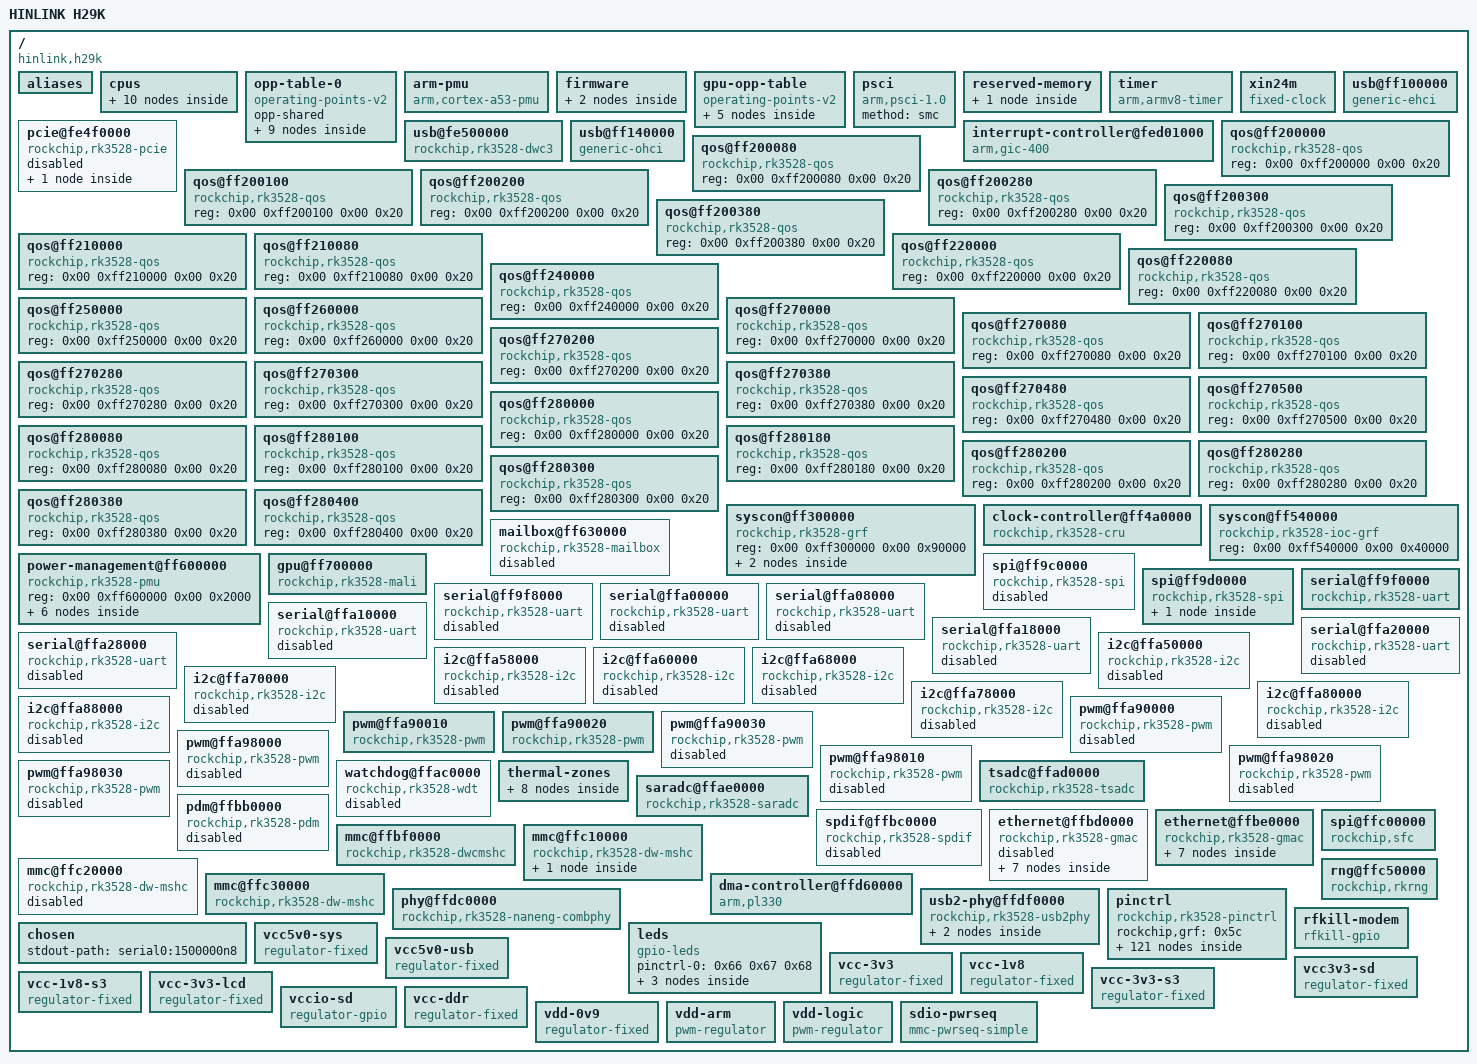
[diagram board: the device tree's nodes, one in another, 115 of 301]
/dts-v1/;

/ {
	interrupt-parent = <0x01>;
	#address-cells = <0x02>;
	#size-cells = <0x02>;
	model = "HINLINK H29K";
	compatible = "hinlink,h29k\0rockchip,rk3528";

	aliases {
		gpio0 = "/pinctrl/gpio@ff610000";
		gpio1 = "/pinctrl/gpio@ffaf0000";
		gpio2 = "/pinctrl/gpio@ffb00000";
		gpio3 = "/pinctrl/gpio@ffb10000";
		gpio4 = "/pinctrl/gpio@ffb20000";
		i2c0 = "/i2c@ffa50000";
		i2c1 = "/i2c@ffa58000";
		i2c2 = "/i2c@ffa60000";
		i2c3 = "/i2c@ffa68000";
		i2c4 = "/i2c@ffa70000";
		i2c5 = "/i2c@ffa78000";
		i2c6 = "/i2c@ffa80000";
		i2c7 = "/i2c@ffa88000";
		serial0 = "/serial@ff9f0000";
		serial1 = "/serial@ff9f8000";
		serial2 = "/serial@ffa00000";
		serial3 = "/serial@ffa08000";
		serial4 = "/serial@ffa10000";
		serial5 = "/serial@ffa18000";
		serial6 = "/serial@ffa20000";
		serial7 = "/serial@ffa28000";
		spi0 = "/spi@ff9c0000";
		spi1 = "/spi@ff9d0000";
		spi2 = "/spi@ffc00000";
		mmc0 = "/mmc@ffbf0000";
		mmc1 = "/mmc@ffc30000";
		mmc2 = "/mmc@ffc10000";
		ethernet0 = "/ethernet@ffbe0000";
		led-boot = "/leds/work";
		led-failsafe = "/leds/work";
		led-running = "/leds/work";
		led-upgrade = "/leds/work";
	};

	cpus {
		#address-cells = <0x02>;
		#size-cells = <0x00>;

		cpu-map {

			cluster0 {

				core0 {
					cpu = <0x02>;
				};

				core1 {
					cpu = <0x03>;
				};

				core2 {
					cpu = <0x04>;
				};

				core3 {
					cpu = <0x05>;
				};
			};
		};

		cpu@0 {
			device_type = "cpu";
			compatible = "arm,cortex-a53";
			reg = <0x00 0x00>;
			clocks = <0x06 0x15>;
			assigned-clocks = <0x06 0x15>;
			assigned-clock-rates = <0x47868c00>;
			dynamic-power-coefficient = <0x93>;
			#cooling-cells = <0x02>;
			enable-method = "psci";
			operating-points-v2 = <0x07>;
			cpu-supply = <0x08>;
			phandle = <0x02>;
		};

		cpu@1 {
			device_type = "cpu";
			compatible = "arm,cortex-a53";
			reg = <0x00 0x01>;
			clocks = <0x06 0x15>;
			dynamic-power-coefficient = <0x93>;
			#cooling-cells = <0x02>;
			enable-method = "psci";
			operating-points-v2 = <0x07>;
			cpu-supply = <0x08>;
			phandle = <0x03>;
		};

		cpu@2 {
			device_type = "cpu";
			compatible = "arm,cortex-a53";
			reg = <0x00 0x02>;
			clocks = <0x06 0x15>;
			dynamic-power-coefficient = <0x93>;
			#cooling-cells = <0x02>;
			enable-method = "psci";
			operating-points-v2 = <0x07>;
			cpu-supply = <0x08>;
			phandle = <0x04>;
		};

		cpu@3 {
			device_type = "cpu";
			compatible = "arm,cortex-a53";
			reg = <0x00 0x03>;
			clocks = <0x06 0x15>;
			dynamic-power-coefficient = <0x93>;
			#cooling-cells = <0x02>;
			enable-method = "psci";
			operating-points-v2 = <0x07>;
			cpu-supply = <0x08>;
			phandle = <0x05>;
		};
	};

	opp-table-0 {
		compatible = "operating-points-v2";
		opp-shared;
		phandle = <0x07>;

		opp-408000000 {
			opp-hz = <0x00 0x18519600>;
			opp-microvolt = <0xc96a8 0xc96a8 0x10c8e0>;
			clock-latency-ns = <0x9c40>;
			opp-suspend;
		};

		opp-600000000 {
			opp-hz = <0x00 0x23c34600>;
			opp-microvolt = <0xc96a8 0xc96a8 0x10c8e0>;
			clock-latency-ns = <0x9c40>;
		};

		opp-816000000 {
			opp-hz = <0x00 0x30a32c00>;
			opp-microvolt = <0xc96a8 0xc96a8 0x10c8e0>;
			clock-latency-ns = <0x9c40>;
		};

		opp-1008000000 {
			opp-hz = <0x00 0x3c14dc00>;
			opp-microvolt = <0xc96a8 0xc96a8 0x10c8e0>;
			clock-latency-ns = <0x9c40>;
		};

		opp-1200000000 {
			opp-hz = <0x00 0x47868c00>;
			opp-microvolt = <0xc96a8 0xc96a8 0x10c8e0>;
			clock-latency-ns = <0x9c40>;
		};

		opp-1416000000 {
			opp-hz = <0x00 0x54667200>;
			opp-microvolt = <0xeafc4 0xeafc4 0x10c8e0>;
			clock-latency-ns = <0x9c40>;
		};

		opp-1608000000 {
			opp-hz = <0x00 0x5fd82200>;
			opp-microvolt = <0xf7314 0xf7314 0x10c8e0>;
			clock-latency-ns = <0x9c40>;
		};

		opp-1800000000 {
			opp-hz = <0x00 0x6b49d200>;
			opp-microvolt = <0x103664 0x103664 0x10c8e0>;
			clock-latency-ns = <0x9c40>;
		};

		opp-2016000000 {
			opp-hz = <0x00 0x7829b800>;
			opp-microvolt = <0x10c8e0 0x10c8e0 0x10c8e0>;
			clock-latency-ns = <0x9c40>;
		};
	};

	arm-pmu {
		compatible = "arm,cortex-a53-pmu";
		interrupts = <0x00 0xab 0x04 0x00 0xac 0x04 0x00 0xad 0x04 0x00 0xae 0x04>;
		interrupt-affinity = <0x02 0x03 0x04 0x05>;
	};

	firmware {

		scmi {
			compatible = "arm,scmi-smc";
			arm,smc-id = <0x82000010>;
			shmem = <0x09>;
			#address-cells = <0x01>;
			#size-cells = <0x00>;

			protocol@14 {
				reg = <0x14>;
				#clock-cells = <0x01>;
				phandle = <0x06>;
			};
		};
	};

	gpu-opp-table {
		compatible = "operating-points-v2";
		phandle = <0x14>;

		opp-300000000 {
			opp-hz = <0x00 0x11e1a300>;
			opp-microvolt = <0xd59f8 0xd59f8 0xf4240>;
		};

		opp-500000000 {
			opp-hz = <0x00 0x1dcd6500>;
			opp-microvolt = <0xd59f8 0xd59f8 0xf4240>;
		};

		opp-600000000 {
			opp-hz = <0x00 0x23c34600>;
			opp-microvolt = <0xd59f8 0xd59f8 0xf4240>;
		};

		opp-700000000 {
			opp-hz = <0x00 0x29b92700>;
			opp-microvolt = <0xdbba0 0xdbba0 0xf4240>;
		};

		opp-800000000 {
			opp-hz = <0x00 0x2faf0800>;
			opp-microvolt = <0xe7ef0 0xe7ef0 0xf4240>;
		};
	};

	psci {
		compatible = "arm,psci-1.0";
		method = "smc";
	};

	reserved-memory {
		#address-cells = <0x02>;
		#size-cells = <0x02>;
		ranges;

		shmem@10f000 {
			compatible = "arm,scmi-shmem";
			reg = <0x00 0x10f000 0x00 0x100>;
			no-map;
			phandle = <0x09>;
		};
	};

	timer {
		compatible = "arm,armv8-timer";
		interrupts = <0x01 0x0d 0xf08 0x01 0x0e 0xf08 0x01 0x0b 0xf08 0x01 0x0a 0xf08>;
	};

	xin24m {
		compatible = "fixed-clock";
		#clock-cells = <0x00>;
		clock-frequency = <0x16e3600>;
		clock-output-names = "xin24m";
	};

	pcie@fe4f0000 {
		compatible = "rockchip,rk3528-pcie\0rockchip,rk3568-pcie";
		reg = <0x00 0xfe000000 0x00 0x400000 0x00 0xfe4f0000 0x00 0x10000 0x00 0xfc000000 0x00 0x100000>;
		reg-names = "dbi\0apb\0config";
		interrupts = <0x00 0x9e 0x04 0x00 0x9d 0x04 0x00 0x9c 0x04 0x00 0x9b 0x04 0x00 0x9a 0x04 0x00 0x99 0x04>;
		interrupt-names = "msi\0pmc\0sys\0legacy\0msg\0err";
		bus-range = <0x00 0xff>;
		clocks = <0x0a 0xd9 0x0a 0xda 0x0a 0xdb 0x0a 0x9e 0x0a 0xd8 0x0a 0xd7 0x0a 0xdc>;
		clock-names = "aclk\0hclk_slv\0hclk_dbi\0pclk_cru\0aux\0pclk\0pipe";
		device_type = "pci";
		#interrupt-cells = <0x01>;
		interrupt-map-mask = <0x00 0x00 0x00 0x07>;
		interrupt-map = <0x00 0x00 0x00 0x01 0x0b 0x00 0x00 0x00 0x00 0x02 0x0b 0x01 0x00 0x00 0x00 0x03 0x0b 0x02 0x00 0x00 0x00 0x04 0x0b 0x03>;
		linux,pci-domain = <0x00>;
		max-link-speed = <0x02>;
		num-ib-windows = <0x08>;
		num-ob-windows = <0x08>;
		num-viewport = <0x04>;
		num-lanes = <0x01>;
		phys = <0x0c 0x02>;
		phy-names = "pcie-phy";
		ranges = <0x1000000 0x00 0xfc100000 0x00 0xfc100000 0x00 0x100000 0x2000000 0x00 0xfc200000 0x00 0xfc200000 0x00 0x1e00000 0x3000000 0x01 0x00 0x01 0x00 0x00 0x40000000>;
		resets = <0x0a 0x1e3 0x0a 0x1e1 0x0a 0x19b>;
		reset-names = "pwr\0periph\0preset_cru";
		#address-cells = <0x03>;
		#size-cells = <0x02>;
		status = "disabled";

		legacy-interrupt-controller {
			#address-cells = <0x00>;
			#interrupt-cells = <0x01>;
			interrupt-controller;
			interrupt-parent = <0x01>;
			interrupts = <0x00 0x9b 0x01>;
			phandle = <0x0b>;
		};
	};

	usb@fe500000 {
		compatible = "rockchip,rk3528-dwc3\0snps,dwc3";
		reg = <0x00 0xfe500000 0x00 0x400000>;
		interrupts = <0x00 0x98 0x04>;
		clocks = <0x0a 0x106 0x0a 0x107 0x0a 0x105>;
		clock-names = "ref_clk\0suspend_clk\0bus_clk";
		dr_mode = "host";
		phys = <0x0d 0x0c 0x04>;
		phy-names = "usb2-phy\0usb3-phy";
		phy_type = "utmi_wide";
		snps,dis-del-phy-power-chg-quirk;
		snps,dis-tx-ipgap-linecheck-quirk;
		snps,dis-u2-freeclk-exists-quirk;
		snps,dis_enblslpm_quirk;
		snps,dis_u2_susphy_quirk;
		resets = <0x0a 0x211>;
		reset-names = "usb3-otg";
		status = "okay";
	};

	interrupt-controller@fed01000 {
		compatible = "arm,gic-400";
		#interrupt-cells = <0x03>;
		#address-cells = <0x00>;
		interrupt-controller;
		reg = <0x00 0xfed01000 0x00 0x1000 0x00 0xfed02000 0x00 0x2000 0x00 0xfed04000 0x00 0x2000 0x00 0xfed06000 0x00 0x2000>;
		interrupts = <0x01 0x09 0xf08>;
		phandle = <0x01>;
	};

	usb@ff100000 {
		compatible = "generic-ehci";
		reg = <0x00 0xff100000 0x00 0x40000>;
		interrupts = <0x00 0x8f 0x04>;
		clocks = <0x0a 0x1a0 0x0a 0x1a1 0x0e>;
		clock-names = "usbhost\0arbiter\0utmi";
		phys = <0x0f>;
		phy-names = "usb2-phy";
		status = "okay";
	};

	usb@ff140000 {
		compatible = "generic-ohci";
		reg = <0x00 0xff140000 0x00 0x40000>;
		interrupts = <0x00 0x90 0x04>;
		clocks = <0x0a 0x1a0 0x0a 0x1a1 0x0e>;
		clock-names = "usbhost\0arbiter\0utmi";
		phys = <0x0f>;
		phy-names = "usb2-phy";
		status = "okay";
	};

	qos@ff200000 {
		compatible = "rockchip,rk3528-qos\0syscon";
		reg = <0x00 0xff200000 0x00 0x20>;
	};

	qos@ff200080 {
		compatible = "rockchip,rk3528-qos\0syscon";
		reg = <0x00 0xff200080 0x00 0x20>;
	};

	qos@ff200100 {
		compatible = "rockchip,rk3528-qos\0syscon";
		reg = <0x00 0xff200100 0x00 0x20>;
	};

	qos@ff200200 {
		compatible = "rockchip,rk3528-qos\0syscon";
		reg = <0x00 0xff200200 0x00 0x20>;
	};

	qos@ff200280 {
		compatible = "rockchip,rk3528-qos\0syscon";
		reg = <0x00 0xff200280 0x00 0x20>;
	};

	qos@ff200300 {
		compatible = "rockchip,rk3528-qos\0syscon";
		reg = <0x00 0xff200300 0x00 0x20>;
	};

	qos@ff200380 {
		compatible = "rockchip,rk3528-qos\0syscon";
		reg = <0x00 0xff200380 0x00 0x20>;
	};

	qos@ff210000 {
		compatible = "rockchip,rk3528-qos\0syscon";
		reg = <0x00 0xff210000 0x00 0x20>;
	};

	qos@ff210080 {
		compatible = "rockchip,rk3528-qos\0syscon";
		reg = <0x00 0xff210080 0x00 0x20>;
	};

	qos@ff220000 {
		compatible = "rockchip,rk3528-qos\0syscon";
		reg = <0x00 0xff220000 0x00 0x20>;
		phandle = <0x11>;
	};

	qos@ff220080 {
		compatible = "rockchip,rk3528-qos\0syscon";
		reg = <0x00 0xff220080 0x00 0x20>;
		phandle = <0x12>;
	};

	qos@ff240000 {
		compatible = "rockchip,rk3528-qos\0syscon";
		reg = <0x00 0xff240000 0x00 0x20>;
	};

	qos@ff250000 {
		compatible = "rockchip,rk3528-qos\0syscon";
		reg = <0x00 0xff250000 0x00 0x20>;
	};

	qos@ff260000 {
		compatible = "rockchip,rk3528-qos\0syscon";
		reg = <0x00 0xff260000 0x00 0x20>;
	};

	qos@ff270000 {
		compatible = "rockchip,rk3528-qos\0syscon";
		reg = <0x00 0xff270000 0x00 0x20>;
	};

	qos@ff270080 {
		compatible = "rockchip,rk3528-qos\0syscon";
		reg = <0x00 0xff270080 0x00 0x20>;
	};

	qos@ff270100 {
		compatible = "rockchip,rk3528-qos\0syscon";
		reg = <0x00 0xff270100 0x00 0x20>;
	};

	qos@ff270200 {
		compatible = "rockchip,rk3528-qos\0syscon";
		reg = <0x00 0xff270200 0x00 0x20>;
	};

	qos@ff270280 {
		compatible = "rockchip,rk3528-qos\0syscon";
		reg = <0x00 0xff270280 0x00 0x20>;
	};

	qos@ff270300 {
		compatible = "rockchip,rk3528-qos\0syscon";
		reg = <0x00 0xff270300 0x00 0x20>;
	};

	qos@ff270380 {
		compatible = "rockchip,rk3528-qos\0syscon";
		reg = <0x00 0xff270380 0x00 0x20>;
	};

	qos@ff270480 {
		compatible = "rockchip,rk3528-qos\0syscon";
		reg = <0x00 0xff270480 0x00 0x20>;
	};

	qos@ff270500 {
		compatible = "rockchip,rk3528-qos\0syscon";
		reg = <0x00 0xff270500 0x00 0x20>;
	};

	qos@ff280000 {
		compatible = "rockchip,rk3528-qos\0syscon";
		reg = <0x00 0xff280000 0x00 0x20>;
	};

	qos@ff280080 {
		compatible = "rockchip,rk3528-qos\0syscon";
		reg = <0x00 0xff280080 0x00 0x20>;
	};

	qos@ff280100 {
		compatible = "rockchip,rk3528-qos\0syscon";
		reg = <0x00 0xff280100 0x00 0x20>;
	};

	qos@ff280180 {
		compatible = "rockchip,rk3528-qos\0syscon";
		reg = <0x00 0xff280180 0x00 0x20>;
	};

	qos@ff280200 {
		compatible = "rockchip,rk3528-qos\0syscon";
		reg = <0x00 0xff280200 0x00 0x20>;
	};

	qos@ff280280 {
		compatible = "rockchip,rk3528-qos\0syscon";
		reg = <0x00 0xff280280 0x00 0x20>;
	};

	qos@ff280300 {
		compatible = "rockchip,rk3528-qos\0syscon";
		reg = <0x00 0xff280300 0x00 0x20>;
	};

	qos@ff280380 {
		compatible = "rockchip,rk3528-qos\0syscon";
		reg = <0x00 0xff280380 0x00 0x20>;
	};

	qos@ff280400 {
		compatible = "rockchip,rk3528-qos\0syscon";
		reg = <0x00 0xff280400 0x00 0x20>;
	};

	syscon@ff300000 {
		compatible = "rockchip,rk3528-grf\0syscon\0simple-mfd";
		reg = <0x00 0xff300000 0x00 0x90000>;
		phandle = <0x10>;

		grf-clock-controller {
			compatible = "rockchip,rk3528-grf-cru";
			#clock-cells = <0x01>;
			phandle = <0x4f>;
		};

		reboot-mode {
			compatible = "syscon-reboot-mode";
			offset = <0x70200>;
			mode-bootloader = <0x5242c301>;
			mode-fastboot = <0x5242c309>;
			mode-loader = <0x5242c301>;
			mode-normal = <0x5242c300>;
			mode-recovery = <0x5242c303>;
		};
	};

	clock-controller@ff4a0000 {
		compatible = "rockchip,rk3528-cru";
		reg = <0x00 0xff4a0000 0x00 0x30000>;
		rockchip,grf = <0x10>;
		#clock-cells = <0x01>;
		#reset-cells = <0x01>;
		assigned-clocks = <0x0a 0x1ff 0x0a 0x03 0x0a 0x04 0x0a 0x02 0x0a 0x0d 0x0a 0x11 0x0a 0x09 0x0a 0x0a 0x0a 0x0b 0x0a 0x0c 0x0a 0x0e 0x0a 0x0f 0x0a 0x10 0x0a 0x12 0x0a 0x90 0x0a 0x8f 0x0a 0x95 0x0a 0x55 0x0a 0x144 0x0a 0x96 0x0a 0x93>;
		assigned-clock-rates = <0x8000 0x46cf7100 0x3b9aca00 0x3b5dc100 0xee6b280 0x1dcd6500 0x2faf080 0x5f5e100 0x8f0d180 0xbebc200 0x11e1a300 0x1443fd00 0x17d78400 0x23c34600 0x2faf080 0x5f5e100 0x7735940 0x1dcd6500 0x1443fd00 0x11e1a300 0xbebc200>;
		phandle = <0x0a>;
	};

	syscon@ff540000 {
		compatible = "rockchip,rk3528-ioc-grf\0syscon";
		reg = <0x00 0xff540000 0x00 0x40000>;
		phandle = <0x5c>;
	};

	power-management@ff600000 {
		compatible = "rockchip,rk3528-pmu\0syscon\0simple-mfd";
		reg = <0x00 0xff600000 0x00 0x2000>;

		power-controller {
			compatible = "rockchip,rk3528-power-controller";
			#power-domain-cells = <0x01>;
			#address-cells = <0x01>;
			#size-cells = <0x00>;
			phandle = <0x13>;

			pd_gpu@4 {
				reg = <0x04>;
				clocks = <0x0a 0x113 0x0a 0x10e>;
				pm_qos = <0x11 0x12>;
			};

			pd_rkvdec@5 {
				reg = <0x05>;
			};

			pd_rkvenc@6 {
				reg = <0x06>;
			};

			pd_vo@7 {
				reg = <0x07>;
			};

			pd_vpu@8 {
				reg = <0x08>;
			};
		};
	};

	mailbox@ff630000 {
		compatible = "rockchip,rk3528-mailbox\0rockchip,rk3368-mailbox";
		reg = <0x00 0xff630000 0x00 0x200>;
		interrupts = <0x00 0x3c 0x04>;
		clocks = <0x0a 0x20a>;
		clock-names = "pclk_mailbox";
		#mbox-cells = <0x01>;
		status = "disabled";
	};

	gpu@ff700000 {
		compatible = "rockchip,rk3528-mali\0arm,mali-450";
		reg = <0x00 0xff700000 0x00 0x40000>;
		interrupts = <0x00 0x58 0x04 0x00 0x59 0x04 0x00 0x56 0x04 0x00 0x5c 0x04 0x00 0x5d 0x04 0x00 0x5a 0x04 0x00 0x5b 0x04>;
		interrupt-names = "gp\0gpmmu\0pp\0pp0\0ppmmu0\0pp1\0ppmmu1";
		clocks = <0x0a 0x113 0x0a 0x10e>;
		clock-names = "bus\0core";
		assigned-clocks = <0x06 0x16>;
		assigned-clock-rates = <0x11e1a300>;
		power-domains = <0x13 0x04>;
		operating-points-v2 = <0x14>;
		rockchip,grf = <0x10>;
		#cooling-cells = <0x02>;
		status = "okay";
		mali-supply = <0x15>;
		phandle = <0x33>;
	};

	spi@ff9c0000 {
		compatible = "rockchip,rk3528-spi\0rockchip,rk3066-spi";
		reg = <0x00 0xff9c0000 0x00 0x1000>;
		interrupts = <0x00 0x83 0x04>;
		#address-cells = <0x01>;
		#size-cells = <0x00>;
		clocks = <0x0a 0x12a 0x0a 0x129 0x0a 0x12b>;
		clock-names = "spiclk\0apb_pclk\0sclk_in";
		dmas = <0x16 0x19 0x16 0x18>;
		dma-names = "tx\0rx";
		pinctrl-names = "default";
		pinctrl-0 = <0x17 0x18 0x19>;
		status = "disabled";
	};

	spi@ff9d0000 {
		compatible = "rockchip,rk3528-spi\0rockchip,rk3066-spi";
		reg = <0x00 0xff9d0000 0x00 0x1000>;
		interrupts = <0x00 0x84 0x04>;
		#address-cells = <0x01>;
		#size-cells = <0x00>;
		clocks = <0x0a 0xbe 0x0a 0xbd 0x0a 0xbf>;
		clock-names = "spiclk\0apb_pclk\0sclk_in";
		dmas = <0x16 0x1f 0x16 0x1e>;
		dma-names = "tx\0rx";
		pinctrl-names = "default";
		pinctrl-0 = <0x1a 0x1b>;
		status = "okay";
		assigned-clocks = <0x0a 0xbe>;
		assigned-clock-rates = <0xbebc200>;
		num-cs = <0x01>;

		panel@0 {
			compatible = "sitronix,st7789v";
			reg = <0x00>;
			power-supply = <0x1c>;
			pinctrl-names = "default";
			pinctrl-0 = <0x1d>;
			dc-gpios = <0x1e 0x0c 0x00>;
			backlight-gpios = <0x1f 0x00 0x01>;
			spi-max-frequency = <0x5b8d80>;
			width = <0xaa>;
			height = <0x140>;
			buswidth = <0x08>;
			rotate = <0x10e>;
			debug = <0x00>;
			spi-cpol;
			spi-cpha;
		};
	};

	serial@ff9f0000 {
		compatible = "rockchip,rk3528-uart\0snps,dw-apb-uart";
		reg = <0x00 0xff9f0000 0x00 0x100>;
		interrupts = <0x00 0x28 0x04>;
		clocks = <0x0a 0x15 0x0a 0x75>;
		clock-names = "baudclk\0apb_pclk";
		reg-shift = <0x02>;
		reg-io-width = <0x04>;
		dmas = <0x16 0x09 0x16 0x08>;
		status = "okay";
		pinctrl-names = "default";
		pinctrl-0 = <0x20>;
	};

	serial@ff9f8000 {
		compatible = "rockchip,rk3528-uart\0snps,dw-apb-uart";
		reg = <0x00 0xff9f8000 0x00 0x100>;
		interrupts = <0x00 0x29 0x04>;
		clocks = <0x0a 0x18 0x0a 0x13b>;
		clock-names = "baudclk\0apb_pclk";
		reg-shift = <0x02>;
		reg-io-width = <0x04>;
		dmas = <0x16 0x0b 0x16 0x0a>;
		status = "disabled";
	};

	serial@ffa00000 {
		compatible = "rockchip,rk3528-uart\0snps,dw-apb-uart";
		reg = <0x00 0xffa00000 0x00 0x100>;
		interrupts = <0x00 0x2a 0x04>;
		clocks = <0x0a 0x1b 0x0a 0xc0>;
		clock-names = "baudclk\0apb_pclk";
		reg-shift = <0x02>;
		reg-io-width = <0x04>;
		dmas = <0x16 0x0d 0x16 0x0c>;
		status = "disabled";
	};

	serial@ffa08000 {
		compatible = "rockchip,rk3528-uart\0snps,dw-apb-uart";
		reg = <0x00 0xffa08000 0x00 0x100>;
		interrupts = <0x00 0x2b 0x04>;
		clocks = <0x0a 0x1e 0x0a 0x13d>;
		clock-names = "baudclk\0apb_pclk";
		reg-shift = <0x02>;
		reg-io-width = <0x04>;
		dmas = <0x16 0x0f 0x16 0x0e>;
		status = "disabled";
	};

	serial@ffa10000 {
		compatible = "rockchip,rk3528-uart\0snps,dw-apb-uart";
		reg = <0x00 0xffa10000 0x00 0x100>;
		interrupts = <0x00 0x2c 0x04>;
		clocks = <0x0a 0x21 0x0a 0x1a4>;
		clock-names = "baudclk\0apb_pclk";
		reg-shift = <0x02>;
		reg-io-width = <0x04>;
		dmas = <0x16 0x11 0x16 0x10>;
		status = "disabled";
	};

	serial@ffa18000 {
		compatible = "rockchip,rk3528-uart\0snps,dw-apb-uart";
		reg = <0x00 0xffa18000 0x00 0x100>;
		interrupts = <0x00 0x2d 0x04>;
		clocks = <0x0a 0x24 0x0a 0xc2>;
		clock-names = "baudclk\0apb_pclk";
		reg-shift = <0x02>;
		reg-io-width = <0x04>;
		dmas = <0x16 0x13 0x16 0x12>;
		status = "disabled";
	};

	serial@ffa20000 {
		compatible = "rockchip,rk3528-uart\0snps,dw-apb-uart";
		reg = <0x00 0xffa20000 0x00 0x100>;
		interrupts = <0x00 0x2e 0x04>;
		clocks = <0x0a 0x27 0x0a 0xc4>;
		clock-names = "baudclk\0apb_pclk";
		reg-shift = <0x02>;
		reg-io-width = <0x04>;
		dmas = <0x16 0x15 0x16 0x14>;
		status = "disabled";
	};

	serial@ffa28000 {
		compatible = "rockchip,rk3528-uart\0snps,dw-apb-uart";
		reg = <0x00 0xffa28000 0x00 0x100>;
		interrupts = <0x00 0x2f 0x04>;
		clocks = <0x0a 0x2a 0x0a 0xc6>;
		clock-names = "baudclk\0apb_pclk";
		reg-shift = <0x02>;
		reg-io-width = <0x04>;
		dmas = <0x16 0x17 0x16 0x16>;
		status = "disabled";
	};

	i2c@ffa50000 {
		compatible = "rockchip,rk3528-i2c\0rockchip,rk3399-i2c";
		reg = <0x00 0xffa50000 0x00 0x1000>;
		clocks = <0x0a 0x127 0x0a 0x126>;
		clock-names = "i2c\0pclk";
		interrupts = <0x00 0x3d 0x04>;
		pinctrl-names = "default";
		pinctrl-0 = <0x21>;
		#address-cells = <0x01>;
		#size-cells = <0x00>;
		status = "disabled";
	};

	i2c@ffa58000 {
		compatible = "rockchip,rk3528-i2c\0rockchip,rk3399-i2c";
		reg = <0x00 0xffa58000 0x00 0x1000>;
		clocks = <0x0a 0x125 0x0a 0x124>;
		clock-names = "i2c\0pclk";
		interrupts = <0x00 0x3e 0x04>;
		pinctrl-names = "default";
		pinctrl-0 = <0x22>;
		#address-cells = <0x01>;
		#size-cells = <0x00>;
		status = "disabled";
	};

	i2c@ffa60000 {
		compatible = "rockchip,rk3528-i2c\0rockchip,rk3399-i2c";
		reg = <0x00 0xffa60000 0x00 0x1000>;
		clocks = <0x0a 0x1f2 0x0a 0x1f1>;
		clock-names = "i2c\0pclk";
		interrupts = <0x00 0x3f 0x04>;
		pinctrl-names = "default";
		pinctrl-0 = <0x23>;
		#address-cells = <0x01>;
		#size-cells = <0x00>;
		status = "disabled";
	};

	i2c@ffa68000 {
		compatible = "rockchip,rk3528-i2c\0rockchip,rk3399-i2c";
		reg = <0x00 0xffa68000 0x00 0x1000>;
		clocks = <0x0a 0xc9 0x0a 0xc8>;
		clock-names = "i2c\0pclk";
		interrupts = <0x00 0x40 0x04>;
		pinctrl-names = "default";
		pinctrl-0 = <0x24>;
		#address-cells = <0x01>;
		#size-cells = <0x00>;
		status = "disabled";
	};

	i2c@ffa70000 {
		compatible = "rockchip,rk3528-i2c\0rockchip,rk3399-i2c";
		reg = <0x00 0xffa70000 0x00 0x1000>;
		clocks = <0x0a 0x1a7 0x0a 0x1a6>;
		clock-names = "i2c\0pclk";
		interrupts = <0x00 0x41 0x04>;
		pinctrl-names = "default";
		pinctrl-0 = <0x25>;
		#address-cells = <0x01>;
		#size-cells = <0x00>;
		status = "disabled";
	};

	i2c@ffa78000 {
		compatible = "rockchip,rk3528-i2c\0rockchip,rk3399-i2c";
		reg = <0x00 0xffa78000 0x00 0x1000>;
		clocks = <0x0a 0xcb 0x0a 0xca>;
		clock-names = "i2c\0pclk";
		interrupts = <0x00 0x42 0x04>;
		pinctrl-names = "default";
		pinctrl-0 = <0x26>;
		#address-cells = <0x01>;
		#size-cells = <0x00>;
		status = "disabled";
	};

	i2c@ffa80000 {
		compatible = "rockchip,rk3528-i2c\0rockchip,rk3399-i2c";
		reg = <0x00 0xffa80000 0x00 0x1000>;
		clocks = <0x0a 0xcd 0x0a 0xcc>;
		clock-names = "i2c\0pclk";
		interrupts = <0x00 0x43 0x04>;
		pinctrl-names = "default";
		pinctrl-0 = <0x27>;
		#address-cells = <0x01>;
		#size-cells = <0x00>;
		status = "disabled";
	};

	i2c@ffa88000 {
		compatible = "rockchip,rk3528-i2c\0rockchip,rk3399-i2c";
		reg = <0x00 0xffa88000 0x00 0x1000>;
		clocks = <0x0a 0x1a9 0x0a 0x1a8>;
		clock-names = "i2c\0pclk";
		interrupts = <0x00 0x44 0x04>;
		pinctrl-names = "default";
		pinctrl-0 = <0x28>;
		#address-cells = <0x01>;
		#size-cells = <0x00>;
		status = "disabled";
	};

	pwm@ffa90000 {
		compatible = "rockchip,rk3528-pwm\0rockchip,rk3328-pwm";
		reg = <0x00 0xffa90000 0x00 0x10>;
		clocks = <0x0a 0x7f 0x0a 0x7e>;
		clock-names = "pwm\0pclk";
		pinctrl-0 = <0x29>;
		pinctrl-names = "active";
		#pwm-cells = <0x03>;
		status = "disabled";
	};

	pwm@ffa90010 {
		compatible = "rockchip,rk3528-pwm\0rockchip,rk3328-pwm";
		reg = <0x00 0xffa90010 0x00 0x10>;
		clocks = <0x0a 0x7f 0x0a 0x7e>;
		clock-names = "pwm\0pclk";
		pinctrl-0 = <0x2a>;
		pinctrl-names = "active";
		#pwm-cells = <0x03>;
		status = "okay";
		phandle = <0x69>;
	};

	pwm@ffa90020 {
		compatible = "rockchip,rk3528-pwm\0rockchip,rk3328-pwm";
		reg = <0x00 0xffa90020 0x00 0x10>;
		clocks = <0x0a 0x7f 0x0a 0x7e>;
		clock-names = "pwm\0pclk";
		pinctrl-0 = <0x2b>;
		pinctrl-names = "active";
		#pwm-cells = <0x03>;
		status = "okay";
		phandle = <0x6a>;
	};

	pwm@ffa90030 {
		compatible = "rockchip,rk3528-pwm\0rockchip,rk3328-pwm";
		reg = <0x00 0xffa90030 0x00 0x10>;
		clocks = <0x0a 0x7f 0x0a 0x7e>;
		clock-names = "pwm\0pclk";
		pinctrl-0 = <0x2c>;
		pinctrl-names = "active";
		#pwm-cells = <0x03>;
		status = "disabled";
	};

	pwm@ffa98000 {
		compatible = "rockchip,rk3528-pwm\0rockchip,rk3328-pwm";
		reg = <0x00 0xffa98000 0x00 0x10>;
		clocks = <0x0a 0x82 0x0a 0x81>;
		clock-names = "pwm\0pclk";
		pinctrl-0 = <0x2d>;
		pinctrl-names = "active";
		#pwm-cells = <0x03>;
		status = "disabled";
	};

	pwm@ffa98010 {
		compatible = "rockchip,rk3528-pwm\0rockchip,rk3328-pwm";
		reg = <0x00 0xffa98010 0x00 0x10>;
		clocks = <0x0a 0x82 0x0a 0x81>;
		clock-names = "pwm\0pclk";
		pinctrl-0 = <0x2e>;
		pinctrl-names = "active";
		#pwm-cells = <0x03>;
		status = "disabled";
	};

	pwm@ffa98020 {
		compatible = "rockchip,rk3528-pwm\0rockchip,rk3328-pwm";
		reg = <0x00 0xffa98020 0x00 0x10>;
		clocks = <0x0a 0x82 0x0a 0x81>;
		clock-names = "pwm\0pclk";
		pinctrl-0 = <0x2f>;
		pinctrl-names = "active";
		#pwm-cells = <0x03>;
		status = "disabled";
	};

	pwm@ffa98030 {
		compatible = "rockchip,rk3528-pwm\0rockchip,rk3328-pwm";
		reg = <0x00 0xffa98030 0x00 0x10>;
		clocks = <0x0a 0x82 0x0a 0x81>;
		clock-names = "pwm\0pclk";
		pinctrl-0 = <0x30>;
		pinctrl-names = "active";
		#pwm-cells = <0x03>;
		status = "disabled";
	};

	watchdog@ffac0000 {
		compatible = "rockchip,rk3528-wdt\0snps,dw-wdt";
		reg = <0x00 0xffac0000 0x00 0x100>;
		clocks = <0x0a 0x73 0x0a 0x72>;
		clock-names = "tclk\0pclk";
		interrupts = <0x00 0x1c 0x04>;
		status = "disabled";
	};

	thermal-zones {

		soc-thermal {
			polling-delay-passive = <0x14>;
			polling-delay = <0x3e8>;
			sustainable-power = <0x27e>;
			thermal-sensors = <0x31 0x00>;

			trips {

				trip-point-0 {
					temperature = <0x17318>;
					hysteresis = <0x7d0>;
					type = "passive";
				};

				trip-point-1 {
					temperature = <0x1adb0>;
					hysteresis = <0x7d0>;
					type = "passive";
					phandle = <0x32>;
				};

				soc-crit {
					temperature = <0x1d4c0>;
					hysteresis = <0x7d0>;
					type = "critical";
				};
			};

			cooling-maps {

				map0 {
					trip = <0x32>;
					cooling-device = <0x02 0xffffffff 0xffffffff 0x03 0xffffffff 0xffffffff 0x04 0xffffffff 0xffffffff 0x05 0xffffffff 0xffffffff>;
					contribution = <0x400>;
				};

				map1 {
					trip = <0x32>;
					cooling-device = <0x33 0xffffffff 0xffffffff>;
					contribution = <0x400>;
				};
			};
		};
	};

	tsadc@ffad0000 {
		compatible = "rockchip,rk3528-tsadc";
		reg = <0x00 0xffad0000 0x00 0x400>;
		rockchip,grf = <0x10>;
		interrupts = <0x00 0x8b 0x04>;
		clocks = <0x0a 0x103 0x0a 0x104 0x0a 0x102>;
		clock-names = "tsadc\0tsadc_tsen\0apb_pclk";
		assigned-clocks = <0x0a 0x103 0x0a 0x104>;
		assigned-clock-rates = <0x124f80 0xb71b00>;
		resets = <0x0a 0x20f 0x0a 0x20e>;
		reset-names = "tsadc\0tsadc-apb";
		rockchip,hw-tshut-temp = <0x1d4c0>;
		rockchip,hw-tshut-mode = <0x00>;
		rockchip,hw-tshut-polarity = <0x00>;
		#thermal-sensor-cells = <0x01>;
		status = "okay";
		phandle = <0x31>;
	};

	saradc@ffae0000 {
		compatible = "rockchip,rk3528-saradc";
		reg = <0x00 0xffae0000 0x00 0x10000>;
		interrupts = <0x00 0x8c 0x04>;
		clocks = <0x0a 0x101 0x0a 0x100>;
		clock-names = "saradc\0apb_pclk";
		resets = <0x0a 0x20b>;
		reset-names = "saradc-apb";
		#io-channel-cells = <0x01>;
		status = "okay";
		vref-supply = <0x34>;
	};

	pdm@ffbb0000 {
		compatible = "rockchip,rk3528-pdm\0rockchip,rk3568-pdm";
		reg = <0x00 0xffbb0000 0x00 0x1000>;
		clocks = <0x0a 0x137 0x0a 0x136>;
		clock-names = "pdm_clk\0pdm_hclk";
		dmas = <0x16 0x06>;
		dma-names = "rx";
		pinctrl-names = "default";
		pinctrl-0 = <0x35 0x36 0x37 0x38 0x39 0x3a>;
		#sound-dai-cells = <0x00>;
		status = "disabled";
	};

	spdif@ffbc0000 {
		compatible = "rockchip,rk3528-spdif\0rockchip,rk3568-spdif";
		reg = <0x00 0xffbc0000 0x00 0x1000>;
		interrupts = <0x00 0x82 0x04>;
		clock-names = "mclk\0hclk";
		clocks = <0x0a 0x135 0x0a 0x134>;
		dmas = <0x16 0x07>;
		dma-names = "tx";
		pinctrl-names = "default";
		pinctrl-0 = <0x3b>;
		#sound-dai-cells = <0x00>;
		status = "disabled";
	};

	ethernet@ffbd0000 {
		compatible = "rockchip,rk3528-gmac\0snps,dwmac-4.20a";
		reg = <0x00 0xffbd0000 0x00 0x10000>;
		interrupts = <0x00 0x71 0x04 0x00 0x74 0x04>;
		interrupt-names = "macirq\0eth_wake_irq";
		clocks = <0x0a 0x17b 0x0a 0x17c 0x0a 0x17e 0x0a 0x17d 0x0a 0x17a 0x0a 0x179>;
		clock-names = "stmmaceth\0clk_mac_ref\0mac_clk_rx\0mac_clk_tx\0pclk_mac\0aclk_mac";
		resets = <0x0a 0x29a>;
		reset-names = "stmmaceth";
		rockchip,grf = <0x10>;
		snps,axi-config = <0x3c>;
		snps,mixed-burst;
		snps,mtl-rx-config = <0x3d>;
		snps,mtl-tx-config = <0x3e>;
		snps,tso;
		phy-mode = "rmii";
		clock_in_out = "input";
		phy-handle = <0x3f>;
		status = "disabled";

		mdio {
			compatible = "snps,dwmac-mdio";
			#address-cells = <0x01>;
			#size-cells = <0x00>;

			ethernet-phy@2 {
				compatible = "ethernet-phy-ieee802.3-c22";
				reg = <0x02>;
				clocks = <0x0a 0x18e>;
				resets = <0x0a 0x2a3>;
				phandle = <0x3f>;
			};
		};

		stmmac-axi-config {
			snps,blen = <0x00 0x00 0x00 0x00 0x10 0x08 0x04>;
			snps,rd_osr_lmt = <0x08>;
			snps,wr_osr_lmt = <0x04>;
			phandle = <0x3c>;
		};

		rx-queues-config {
			snps,rx-queues-to-use = <0x01>;
			phandle = <0x3d>;

			queue0 {
			};
		};

		tx-queues-config {
			snps,tx-queues-to-use = <0x01>;
			phandle = <0x3e>;

			queue0 {
			};
		};
	};

	ethernet@ffbe0000 {
		compatible = "rockchip,rk3528-gmac\0snps,dwmac-4.20a";
		reg = <0x00 0xffbe0000 0x00 0x10000>;
		interrupts = <0x00 0x79 0x04 0x00 0x7c 0x04>;
		interrupt-names = "macirq\0eth_wake_irq";
		clocks = <0x0a 0xd2 0x0a 0xd1 0x0a 0xcf 0x0a 0xce>;
		clock-names = "stmmaceth\0clk_mac_ref\0pclk_mac\0aclk_mac";
		resets = <0x0a 0x1c5>;
		reset-names = "stmmaceth";
		rockchip,grf = <0x10>;
		snps,axi-config = <0x40>;
		snps,mixed-burst;
		snps,mtl-rx-config = <0x41>;
		snps,mtl-tx-config = <0x42>;
		snps,tso;
		status = "okay";
		clock_in_out = "output";
		pinctrl-names = "default";
		pinctrl-0 = <0x43 0x44 0x45 0x46 0x47>;
		phy-handle = <0x48>;
		phy-mode = "rgmii-id";
		phy-supply = <0x49>;
		snps,reset-active-low;
		snps,reset-delays-us = <0x00 0x4e20 0x186a0>;
		snps,reset-gpio = <0x4a 0x12 0x01>;

		mdio {
			compatible = "snps,dwmac-mdio";
			#address-cells = <0x01>;
			#size-cells = <0x00>;

			phy@1 {
				compatible = "ethernet-phy-ieee802.3-c22";
				reg = <0x01>;
				phandle = <0x48>;
			};
		};

		stmmac-axi-config {
			snps,wr_osr_lmt = <0x04>;
			snps,rd_osr_lmt = <0x08>;
			snps,blen = <0x00 0x00 0x00 0x00 0x10 0x08 0x04>;
			phandle = <0x40>;
		};

		rx-queues-config {
			snps,rx-queues-to-use = <0x01>;
			phandle = <0x41>;

			queue0 {
			};
		};

		tx-queues-config {
			snps,tx-queues-to-use = <0x01>;
			phandle = <0x42>;

			queue0 {
			};
		};
	};

	mmc@ffbf0000 {
		compatible = "rockchip,rk3528-dwcmshc\0rockchip,rk3588-dwcmshc";
		reg = <0x00 0xffbf0000 0x00 0x10000>;
		interrupts = <0x00 0x88 0x04>;
		assigned-clocks = <0x0a 0xa6 0x0a 0xa7 0x0a 0xa3>;
		assigned-clock-rates = <0xbebc200 0x16e3600 0xbebc200>;
		clocks = <0x0a 0xa3 0x0a 0xa4 0x0a 0xa5 0x0a 0xa6 0x0a 0xa7>;
		clock-names = "core\0bus\0axi\0block\0timer";
		resets = <0x0a 0x19f 0x0a 0x1a0 0x0a 0x1a1 0x0a 0x1a2 0x0a 0x1a3>;
		reset-names = "core\0bus\0axi\0block\0timer";
		max-frequency = <0xbebc200>;
		status = "okay";
		bus-width = <0x08>;
		mmc-hs200-1_8v;
		non-removable;
		pinctrl-names = "default";
		pinctrl-0 = <0x4b 0x4c 0x4d 0x4e>;
		vmmc-supply = <0x49>;
		vqmmc-supply = <0x34>;
	};

	spi@ffc00000 {
		compatible = "rockchip,sfc";
		reg = <0x00 0xffc00000 0x00 0x4000>;
		interrupts = <0x00 0x87 0x04>;
		clocks = <0x0a 0xa1 0x0a 0xa0>;
		clock-names = "clk_sfc\0hclk_sfc";
		assigned-clocks = <0x0a 0xa1>;
		assigned-clock-rates = <0x5f5e100>;
		#address-cells = <0x01>;
		#size-cells = <0x00>;
		status = "okay";
	};

	mmc@ffc10000 {
		compatible = "rockchip,rk3528-dw-mshc\0rockchip,rk3288-dw-mshc";
		reg = <0x00 0xffc10000 0x00 0x4000>;
		interrupts = <0x00 0x89 0x04>;
		clocks = <0x0a 0xf1 0x0a 0xf0 0x4f 0x03 0x4f 0x04>;
		clock-names = "biu\0ciu\0ciu-drive\0ciu-sample";
		fifo-depth = <0x100>;
		max-frequency = <0xbebc200>;
		resets = <0x0a 0x202>;
		reset-names = "reset";
		status = "okay";
		#address-cells = <0x01>;
		#size-cells = <0x00>;
		bus-width = <0x04>;
		cap-sd-highspeed;
		cap-sdio-irq;
		keep-power-in-suspend;
		mmc-pwrseq = <0x50>;
		pinctrl-names = "default";
		pinctrl-0 = <0x51 0x52 0x53>;
		post-power-on-delay-ms = <0x32>;
		non-removable;
		sd-uhs-sdr104;

		sdio_wifi@1 {
			reg = <0x01>;
			interrupt-parent = <0x1e>;
			interrupts = <0x07 0x04>;
			interrupt-names = "host-wake";
			pinctrl-names = "default";
			pinctrl-0 = <0x54>;
		};
	};

	mmc@ffc20000 {
		compatible = "rockchip,rk3528-dw-mshc\0rockchip,rk3288-dw-mshc";
		reg = <0x00 0xffc20000 0x00 0x4000>;
		interrupts = <0x00 0x8a 0x04>;
		clocks = <0x0a 0xf5 0x0a 0xf4 0x4f 0x05 0x4f 0x06>;
		clock-names = "biu\0ciu\0ciu-drive\0ciu-sample";
		fifo-depth = <0x100>;
		max-frequency = <0x8f0d180>;
		resets = <0x0a 0x204>;
		reset-names = "reset";
		status = "disabled";
	};

	mmc@ffc30000 {
		compatible = "rockchip,rk3528-dw-mshc\0rockchip,rk3288-dw-mshc";
		reg = <0x00 0xffc30000 0x00 0x4000>;
		interrupts = <0x00 0x85 0x04>;
		clocks = <0x0a 0x198 0x0a 0x197 0x4f 0x01 0x4f 0x02>;
		clock-names = "biu\0ciu\0ciu-drive\0ciu-sample";
		fifo-depth = <0x100>;
		max-frequency = <0x8f0d180>;
		resets = <0x0a 0x2a9>;
		reset-names = "reset";
		rockchip,use-v2-tuning;
		status = "okay";
		bus-width = <0x04>;
		cap-sd-highspeed;
		disable-wp;
		pinctrl-names = "default";
		pinctrl-0 = <0x55 0x56 0x57 0x58>;
		rockchip,default-sample-phase = <0x5a>;
		sd-uhs-sdr12;
		sd-uhs-sdr25;
		sd-uhs-sdr50;
		sd-uhs-sdr104;
		vmmc-supply = <0x59>;
		vqmmc-supply = <0x5a>;
	};

	rng@ffc50000 {
		compatible = "rockchip,rkrng";
		reg = <0x00 0xffc50000 0x00 0x200>;
		interrupts = <0x00 0x17 0x04>;
		clocks = <0x06 0x20>;
		clock-names = "hclk_trng";
		resets = <0x0a 0xa3>;
		reset-names = "reset";
		status = "okay";
	};

	dma-controller@ffd60000 {
		compatible = "arm,pl330\0arm,primecell";
		reg = <0x00 0xffd60000 0x00 0x4000>;
		interrupts = <0x00 0x00 0x04 0x00 0x01 0x04 0x00 0x02 0x04 0x00 0x03 0x04 0x00 0x04 0x04 0x00 0x05 0x04 0x00 0x06 0x04 0x00 0x07 0x04 0x00 0x10 0x04>;
		arm,pl330-periph-burst;
		clocks = <0x0a 0x68>;
		clock-names = "apb_pclk";
		#dma-cells = <0x01>;
		phandle = <0x16>;
	};

	phy@ffdc0000 {
		compatible = "rockchip,rk3528-naneng-combphy";
		reg = <0x00 0xffdc0000 0x00 0x10000>;
		clocks = <0x0a 0x91 0x0a 0xdc 0x0a 0xdd>;
		clock-names = "ref\0apb\0pipe";
		assigned-clocks = <0x0a 0x91>;
		assigned-clock-rates = <0x5f5e100>;
		resets = <0x0a 0x1e6 0x0a 0x1e2>;
		reset-names = "apb\0phy";
		rockchip,pipe-grf = <0x10>;
		rockchip,pipe-phy-grf = <0x10>;
		#phy-cells = <0x01>;
		status = "okay";
		phandle = <0x0c>;
	};

	usb2-phy@ffdf0000 {
		compatible = "rockchip,rk3528-usb2phy";
		reg = <0x00 0xffdf0000 0x00 0x10000>;
		clocks = <0x0a 0x1ab 0x0a 0x1aa>;
		clock-names = "phyclk\0apb_pclk";
		rockchip,usbgrf = <0x10>;
		#clock-cells = <0x00>;
		status = "okay";
		phandle = <0x0e>;

		otg-port {
			#phy-cells = <0x00>;
			interrupts = <0x00 0x92 0x04 0x00 0x93 0x04 0x00 0x94 0x04>;
			interrupt-names = "otg-bvalid\0otg-id\0linestate";
			status = "okay";
			phy-supply = <0x5b>;
			vbus-supply = <0x49>;
			phandle = <0x0d>;
		};

		host-port {
			#phy-cells = <0x00>;
			interrupts = <0x00 0x96 0x04>;
			interrupt-names = "linestate";
			status = "okay";
			phy-supply = <0x5b>;
			phandle = <0x0f>;
		};
	};

	pinctrl {
		compatible = "rockchip,rk3528-pinctrl";
		rockchip,grf = <0x5c>;
		#address-cells = <0x02>;
		#size-cells = <0x02>;
		ranges;
		phandle = <0x5d>;

		gpio@ff610000 {
			compatible = "rockchip,gpio-bank";
			reg = <0x00 0xff610000 0x00 0x200>;
			interrupts = <0x00 0x47 0x04>;
			clocks = <0x0a 0x1fd 0x0a 0x1fe>;
			gpio-controller;
			#gpio-cells = <0x02>;
			gpio-ranges = <0x5d 0x00 0x00 0x20>;
			interrupt-controller;
			#interrupt-cells = <0x02>;
			phandle = <0x1f>;
		};

		gpio@ffaf0000 {
			compatible = "rockchip,gpio-bank";
			reg = <0x00 0xffaf0000 0x00 0x200>;
			interrupts = <0x00 0x49 0x04>;
			clocks = <0x0a 0xa8 0x0a 0xa9>;
			gpio-controller;
			#gpio-cells = <0x02>;
			gpio-ranges = <0x5d 0x00 0x20 0x20>;
			interrupt-controller;
			#interrupt-cells = <0x02>;
			phandle = <0x1e>;
		};

		gpio@ffb00000 {
			compatible = "rockchip,gpio-bank";
			reg = <0x00 0xffb00000 0x00 0x200>;
			interrupts = <0x00 0x4b 0x04>;
			clocks = <0x0a 0x194 0x0a 0x195>;
			gpio-controller;
			#gpio-cells = <0x02>;
			gpio-ranges = <0x5d 0x00 0x40 0x20>;
			interrupt-controller;
			#interrupt-cells = <0x02>;
		};

		gpio@ffb10000 {
			compatible = "rockchip,gpio-bank";
			reg = <0x00 0xffb10000 0x00 0x200>;
			interrupts = <0x00 0x4c 0x04>;
			clocks = <0x0a 0xba 0x0a 0xbb>;
			gpio-controller;
			#gpio-cells = <0x02>;
			gpio-ranges = <0x5d 0x00 0x60 0x20>;
			interrupt-controller;
			#interrupt-cells = <0x02>;
		};

		gpio@ffb20000 {
			compatible = "rockchip,gpio-bank";
			reg = <0x00 0xffb20000 0x00 0x200>;
			interrupts = <0x00 0x4e 0x04>;
			clocks = <0x0a 0x12c 0x0a 0x12d>;
			gpio-controller;
			#gpio-cells = <0x02>;
			gpio-ranges = <0x5d 0x00 0x80 0x20>;
			interrupt-controller;
			#interrupt-cells = <0x02>;
			phandle = <0x4a>;
		};

		pcfg-pull-up {
			bias-pull-up;
			phandle = <0x63>;
		};

		pcfg-pull-down {
			bias-pull-down;
			phandle = <0x64>;
		};

		pcfg-pull-none {
			bias-disable;
			phandle = <0x5e>;
		};

		pcfg-pull-none-drv-level-0 {
			bias-disable;
			drive-strength = <0x00>;
			phandle = <0x62>;
		};

		pcfg-pull-none-drv-level-2 {
			bias-disable;
			drive-strength = <0x02>;
			phandle = <0x60>;
		};

		pcfg-pull-up-drv-level-2 {
			bias-pull-up;
			drive-strength = <0x02>;
			phandle = <0x5f>;
		};

		pcfg-pull-up-drv-level-6 {
			bias-pull-up;
			drive-strength = <0x06>;
			phandle = <0x65>;
		};

		pcfg-pull-none-smt {
			bias-disable;
			input-schmitt-enable;
			phandle = <0x61>;
		};

		arm {
		};

		clk {
		};

		emmc {

			emmc-bus8 {
				rockchip,pins = <0x01 0x14 0x01 0x5f 0x01 0x15 0x01 0x5f 0x01 0x16 0x01 0x5f 0x01 0x17 0x01 0x5f 0x01 0x18 0x01 0x5f 0x01 0x19 0x01 0x5f 0x01 0x1a 0x01 0x5f 0x01 0x1b 0x01 0x5f>;
				phandle = <0x4b>;
			};

			emmc-clk {
				rockchip,pins = <0x01 0x1d 0x01 0x5f>;
				phandle = <0x4c>;
			};

			emmc-cmd {
				rockchip,pins = <0x01 0x1c 0x01 0x5f>;
				phandle = <0x4d>;
			};

			emmc-strb {
				rockchip,pins = <0x01 0x1f 0x01 0x5e>;
				phandle = <0x4e>;
			};
		};

		eth {
		};

		fephy {
		};

		fspi {
		};

		gpu {
		};

		hdmi {
		};

		hsm {
		};

		i2c0 {

			i2c0m0-xfer {
				rockchip,pins = <0x04 0x14 0x02 0x61 0x04 0x13 0x02 0x61>;
				phandle = <0x21>;
			};
		};

		i2c1 {

			i2c1m0-xfer {
				rockchip,pins = <0x04 0x03 0x02 0x61 0x04 0x02 0x02 0x61>;
				phandle = <0x22>;
			};
		};

		i2c2 {

			i2c2m0-xfer {
				rockchip,pins = <0x00 0x04 0x02 0x61 0x00 0x05 0x02 0x61>;
				phandle = <0x23>;
			};
		};

		i2c3 {

			i2c3m0-xfer {
				rockchip,pins = <0x01 0x00 0x02 0x61 0x01 0x01 0x02 0x61>;
				phandle = <0x24>;
			};
		};

		i2c4 {

			i2c4-xfer {
				rockchip,pins = <0x02 0x00 0x04 0x61 0x02 0x01 0x04 0x61>;
				phandle = <0x25>;
			};
		};

		i2c5 {

			i2c5m0-xfer {
				rockchip,pins = <0x01 0x0a 0x03 0x61 0x01 0x0b 0x03 0x61>;
				phandle = <0x26>;
			};
		};

		i2c6 {

			i2c6m0-xfer {
				rockchip,pins = <0x03 0x0a 0x05 0x61 0x03 0x0b 0x05 0x61>;
				phandle = <0x27>;
			};
		};

		i2c7 {

			i2c7-xfer {
				rockchip,pins = <0x02 0x05 0x04 0x61 0x02 0x06 0x04 0x61>;
				phandle = <0x28>;
			};
		};

		i2s0 {
		};

		i2s1 {
		};

		jtag {
		};

		pcie {
		};

		pdm {

			pdm-clk0 {
				rockchip,pins = <0x04 0x0d 0x03 0x5e>;
				phandle = <0x35>;
			};

			pdm-clk1 {
				rockchip,pins = <0x04 0x04 0x03 0x5e>;
				phandle = <0x36>;
			};

			pdm-sdi0 {
				rockchip,pins = <0x04 0x0a 0x03 0x5e>;
				phandle = <0x37>;
			};

			pdm-sdi1 {
				rockchip,pins = <0x04 0x09 0x03 0x5e>;
				phandle = <0x38>;
			};

			pdm-sdi2 {
				rockchip,pins = <0x04 0x0b 0x03 0x5e>;
				phandle = <0x39>;
			};

			pdm-sdi3 {
				rockchip,pins = <0x04 0x11 0x03 0x5e>;
				phandle = <0x3a>;
			};
		};

		pmu {
		};

		pwm0 {

			pwm0m0-pins {
				rockchip,pins = <0x04 0x13 0x01 0x62>;
				phandle = <0x29>;
			};
		};

		pwm1 {

			pwm1m0-pins {
				rockchip,pins = <0x04 0x14 0x01 0x62>;
				phandle = <0x2a>;
			};
		};

		pwm2 {

			pwm2m0-pins {
				rockchip,pins = <0x04 0x15 0x01 0x62>;
				phandle = <0x2b>;
			};
		};

		pwm3 {

			pwm3m0-pins {
				rockchip,pins = <0x04 0x16 0x01 0x62>;
				phandle = <0x2c>;
			};
		};

		pwm4 {

			pwm4m0-pins {
				rockchip,pins = <0x04 0x0f 0x01 0x62>;
				phandle = <0x2d>;
			};
		};

		pwm5 {

			pwm5m0-pins {
				rockchip,pins = <0x04 0x10 0x01 0x62>;
				phandle = <0x2e>;
			};
		};

		pwm6 {

			pwm6m0-pins {
				rockchip,pins = <0x04 0x11 0x01 0x62>;
				phandle = <0x2f>;
			};
		};

		pwm7 {

			pwm7m0-pins {
				rockchip,pins = <0x04 0x12 0x01 0x62>;
				phandle = <0x30>;
			};
		};

		pwr {
		};

		ref {
		};

		rgmii {

			rgmii-miim {
				rockchip,pins = <0x03 0x0e 0x02 0x60 0x03 0x0f 0x02 0x60>;
				phandle = <0x43>;
			};

			rgmii-rx_bus2 {
				rockchip,pins = <0x03 0x03 0x02 0x5e 0x03 0x02 0x02 0x5e 0x03 0x12 0x02 0x5e>;
				phandle = <0x45>;
			};

			rgmii-tx_bus2 {
				rockchip,pins = <0x03 0x01 0x02 0x60 0x03 0x00 0x02 0x60 0x03 0x10 0x02 0x5e>;
				phandle = <0x44>;
			};

			rgmii-rgmii_clk {
				rockchip,pins = <0x03 0x05 0x02 0x5e 0x03 0x04 0x02 0x60>;
				phandle = <0x46>;
			};

			rgmii-rgmii_bus {
				rockchip,pins = <0x03 0x07 0x02 0x5e 0x03 0x06 0x02 0x5e 0x03 0x09 0x02 0x60 0x03 0x08 0x02 0x60>;
				phandle = <0x47>;
			};
		};

		scr {
		};

		sdio0 {

			sdio0-bus4 {
				rockchip,pins = <0x01 0x00 0x01 0x5f 0x01 0x01 0x01 0x5f 0x01 0x02 0x01 0x5f 0x01 0x03 0x01 0x5f>;
				phandle = <0x51>;
			};

			sdio0-clk {
				rockchip,pins = <0x01 0x05 0x01 0x5f>;
				phandle = <0x53>;
			};

			sdio0-cmd {
				rockchip,pins = <0x01 0x04 0x01 0x5f>;
				phandle = <0x52>;
			};
		};

		sdio1 {
		};

		sdmmc {

			sdmmc-bus4 {
				rockchip,pins = <0x02 0x00 0x01 0x5f 0x02 0x01 0x01 0x5f 0x02 0x02 0x01 0x5f 0x02 0x03 0x01 0x5f>;
				phandle = <0x55>;
			};

			sdmmc-clk {
				rockchip,pins = <0x02 0x05 0x01 0x5f>;
				phandle = <0x56>;
			};

			sdmmc-cmd {
				rockchip,pins = <0x02 0x04 0x01 0x5f>;
				phandle = <0x57>;
			};

			sdmmc-det {
				rockchip,pins = <0x02 0x06 0x01 0x63>;
				phandle = <0x58>;
			};
		};

		spdif {

			spdifm0-pins {
				rockchip,pins = <0x04 0x00 0x01 0x5e>;
				phandle = <0x3b>;
			};
		};

		spi0 {

			spi0-pins {
				rockchip,pins = <0x04 0x0c 0x02 0x60 0x04 0x0b 0x02 0x60 0x04 0x0a 0x02 0x60>;
				phandle = <0x19>;
			};

			spi0-csn0 {
				rockchip,pins = <0x04 0x0e 0x02 0x60>;
				phandle = <0x17>;
			};

			spi0-csn1 {
				rockchip,pins = <0x04 0x11 0x02 0x60>;
				phandle = <0x18>;
			};
		};

		spi1 {
		};

		tsi0 {
		};

		tsi1 {
		};

		uart0 {

			uart0m0-xfer {
				rockchip,pins = <0x04 0x17 0x01 0x63 0x04 0x18 0x01 0x63>;
				phandle = <0x20>;
			};
		};

		uart1 {
		};

		uart2 {
		};

		uart3 {
		};

		uart4 {
		};

		uart5 {
		};

		uart6 {
		};

		uart7 {
		};

		leds {

			led-work-en {
				rockchip,pins = <0x04 0x0f 0x00 0x5e>;
				phandle = <0x68>;
			};

			modem_4g_led {
				rockchip,pins = <0x04 0x10 0x00 0x5e>;
				phandle = <0x66>;
			};

			modem_5g_led {
				rockchip,pins = <0x04 0x13 0x00 0x5e>;
				phandle = <0x67>;
			};
		};

		wifi {

			wifi-enable-h {
				rockchip,pins = <0x01 0x06 0x00 0x5e>;
				phandle = <0x6b>;
			};

			wifi-host-wake {
				rockchip,pins = <0x01 0x07 0x00 0x64>;
				phandle = <0x54>;
			};
		};

		bluetooth {

			bt-enable-h {
				rockchip,pins = <0x01 0x11 0x00 0x64>;
			};

			uart2m1-gpios {
				rockchip,pins = <0x01 0x0a 0x00 0x5e>;
			};
		};

		lcd {

			lcd-dc-pin {
				rockchip,pins = <0x01 0x0c 0x00 0x65>;
				phandle = <0x1d>;
			};

			spi4-custom-pins {
				rockchip,pins = <0x01 0x0e 0x02 0x60 0x01 0x0f 0x02 0x60>;
				phandle = <0x1a>;
			};

			lcd-backlight-pin {
				rockchip,pins = <0x00 0x00 0x00 0x63>;
				phandle = <0x1b>;
			};
		};
	};

	chosen {
		stdout-path = "serial0:1500000n8";
	};

	leds {
		compatible = "gpio-leds";
		pinctrl-names = "default";
		pinctrl-0 = <0x66 0x67 0x68>;

		modem_4g {
			label = "red:modem_4g";
			gpios = <0x4a 0x10 0x01>;
		};

		modem_5g {
			label = "blue:modem_5g";
			gpios = <0x4a 0x13 0x01>;
		};

		work {
			label = "green:work";
			gpios = <0x4a 0x0f 0x01>;
		};
	};

	rfkill-modem {
		compatible = "rfkill-gpio";
		type = "wwan";
		reset-gpios = <0x4a 0x0c 0x01>;
		power-gpios = <0x4a 0x0d 0x01>;
	};

	vcc5v0-sys {
		compatible = "regulator-fixed";
		regulator-name = "vcc5v0_sys";
		regulator-always-on;
		regulator-boot-on;
		regulator-min-microvolt = <0x4c4b40>;
		regulator-max-microvolt = <0x4c4b40>;
		phandle = <0x5b>;
	};

	vcc5v0-usb {
		compatible = "regulator-fixed";
		regulator-name = "vcc5v0_usb";
		regulator-always-on;
		regulator-boot-on;
		regulator-min-microvolt = <0x4c4b40>;
		regulator-max-microvolt = <0x4c4b40>;
		vin-supply = <0x5b>;
	};

	vcc-3v3 {
		compatible = "regulator-fixed";
		regulator-name = "vcc_3v3";
		regulator-always-on;
		regulator-boot-on;
		regulator-min-microvolt = <0x325aa0>;
		regulator-max-microvolt = <0x325aa0>;
		vin-supply = <0x5b>;
		phandle = <0x49>;
	};

	vcc-1v8 {
		compatible = "regulator-fixed";
		regulator-name = "vcc_1v8";
		regulator-always-on;
		regulator-boot-on;
		regulator-min-microvolt = <0x1b7740>;
		regulator-max-microvolt = <0x1b7740>;
		vin-supply = <0x49>;
		phandle = <0x34>;
	};

	vcc3v3-sd {
		compatible = "regulator-fixed";
		gpio = <0x4a 0x01 0x01>;
		regulator-name = "vcc3v3_sd";
		regulator-always-on;
		regulator-boot-on;
		regulator-min-microvolt = <0x325aa0>;
		regulator-max-microvolt = <0x325aa0>;
		vin-supply = <0x49>;
		phandle = <0x59>;
	};

	vcc-3v3-s3 {
		compatible = "regulator-fixed";
		regulator-name = "vcc_3v3_s3";
		regulator-always-on;
		regulator-boot-on;
		regulator-min-microvolt = <0x325aa0>;
		regulator-max-microvolt = <0x325aa0>;
		vin-supply = <0x5b>;
	};

	vcc-1v8-s3 {
		compatible = "regulator-fixed";
		regulator-name = "vcc_1v8_s3";
		regulator-always-on;
		regulator-boot-on;
		regulator-min-microvolt = <0x1b7740>;
		regulator-max-microvolt = <0x1b7740>;
		vin-supply = <0x49>;
	};

	vcc-3v3-lcd {
		compatible = "regulator-fixed";
		regulator-name = "vcc_3v3_lcd";
		regulator-min-microvolt = <0x325aa0>;
		regulator-max-microvolt = <0x325aa0>;
		vin-supply = <0x49>;
		phandle = <0x1c>;
	};

	vccio-sd {
		compatible = "regulator-gpio";
		gpios = <0x4a 0x0e 0x00>;
		regulator-name = "vccio_sd";
		regulator-min-microvolt = <0x1b7740>;
		regulator-max-microvolt = <0x325aa0>;
		states = <0x1b7740 0x00 0x325aa0 0x01>;
		vin-supply = <0x5b>;
		phandle = <0x5a>;
	};

	vcc-ddr {
		compatible = "regulator-fixed";
		regulator-name = "vcc_ddr";
		regulator-always-on;
		regulator-boot-on;
		regulator-min-microvolt = <0x124f80>;
		regulator-max-microvolt = <0x124f80>;
		vin-supply = <0x5b>;
	};

	vdd-0v9 {
		compatible = "regulator-fixed";
		regulator-name = "vdd_0v9";
		regulator-always-on;
		regulator-boot-on;
		regulator-min-microvolt = <0xdbba0>;
		regulator-max-microvolt = <0xdbba0>;
		vin-supply = <0x5b>;
	};

	vdd-arm {
		compatible = "pwm-regulator";
		pwms = <0x69 0x00 0x1388 0x01>;
		regulator-name = "vdd_arm";
		regulator-min-microvolt = <0xb6210>;
		regulator-max-microvolt = <0x125368>;
		regulator-always-on;
		regulator-boot-on;
		regulator-settling-time-up-us = <0xfa>;
		pwm-supply = <0x5b>;
		phandle = <0x08>;
	};

	vdd-logic {
		compatible = "pwm-regulator";
		pwms = <0x6a 0x00 0x1388 0x01>;
		regulator-name = "vdd_logic";
		regulator-min-microvolt = <0xac1e8>;
		regulator-max-microvolt = <0xf59b0>;
		regulator-always-on;
		regulator-boot-on;
		regulator-settling-time-up-us = <0xfa>;
		pwm-supply = <0x5b>;
		phandle = <0x15>;
	};

	sdio-pwrseq {
		compatible = "mmc-pwrseq-simple";
		pinctrl-names = "default";
		pinctrl-0 = <0x6b>;
		reset-gpios = <0x1e 0x06 0x01>;
		phandle = <0x50>;
	};
};
